AUTOSAR XML (schema 00049)
package /MICROSAR/StbM_swc/DataTypes
  21 x impl type:
    StbM_SynchronizedTimeBaseType: range raw 0..65535, implementation-data-type=uint16
    StbM_TimeBaseStatusType:
      compu {mask 1: 0=FALSE (TIMEOUT__FALSE), mask 1: 1=TRUE (TIMEOUT), mask 4: 0=FALSE (SYNC_TO_GATEWAY__FALSE), mask 4: 4=TRUE (SYNC_TO_GATEWAY), mask 8: 0=FALSE (GLOBAL_TIME_BASE__FALSE), mask 8: 8=TRUE (GLOBAL_TIME_BASE), mask 16: 0=FALSE (TIMELEAP_FUTURE__FALSE), mask 16: 16=TRUE (TIMELEAP_FUTURE), mask 32: 0=FALSE (TIMELEAP_PAST__FALSE), mask 32: 32=TRUE (TIMELEAP_PAST)}
      range raw 0..63
      implementation-data-type=uint8
    StbM_CloneConfigType: compu {mask 1: 0=FALSE (DEFERRED_COPY__FALSE), mask 1: 1=TRUE (DEFERRED_COPY), mask 2: 0=FALSE (IMMEDIATE_TX__FALSE), mask 2: 2=TRUE (IMMEDIATE_TX), mask 4: 0=FALSE (APPLY_RATE__FALSE), mask 4: 4=TRUE (APPLY_RATE)}, range raw 0..7, implementation-data-type=uint8
    StbM_TimeStampType: category=STRUCTURE
      4 x element, all with category=TYPE_REFERENCE:
        timeBaseStatus: implementation-data-type=StbM_TimeBaseStatusType
        nanoseconds: implementation-data-type=uint32
        seconds: implementation-data-type=uint32
        secondsHi: implementation-data-type=uint16
    StbM_UserDataType: category=STRUCTURE
      4 x element, all with category=TYPE_REFERENCE, implementation-data-type=uint8:
        userDataLength
        userByte{0..2}
    StbM_RateDeviationType: implementation-data-type=sint16
    StbM_SyncRecordTableHeadType: category=STRUCTURE
      element SynchronizedTimeDomain: implementation-data-type=uint8
      element HWfrequency: implementation-data-type=uint32
      element HWprescaler: implementation-data-type=uint32
    StbM_SyncRecordTableBlockType: category=STRUCTURE
      8 x element, all with category=TYPE_REFERENCE:
        GlbSeconds: implementation-data-type=uint32
        GlbNanoSeconds: implementation-data-type=uint32
        TimeBaseStatus: implementation-data-type=StbM_TimeBaseStatusType
        VirtualLocalTimeLow: implementation-data-type=uint32
        RateDeviation: implementation-data-type=sint16
        LocSeconds: implementation-data-type=uint32
        LocNanoSeconds: implementation-data-type=uint32
        PathDelay: implementation-data-type=uint32
    StbM_OffsetRecordTableHeadType: category=STRUCTURE
      element OffsetTimeDomain: implementation-data-type=uint8
    StbM_OffsetRecordTableBlockType: category=STRUCTURE
      element GlbSeconds: implementation-data-type=uint32
      element GlbNanoSeconds: implementation-data-type=uint32
      element TimeBaseStatus: implementation-data-type=StbM_TimeBaseStatusType
    StbM_PortIdType: category=STRUCTURE
      element clockIdentity: implementation-data-type=uint64
      element portNumber: implementation-data-type=uint16
    StbM_TimeStampShortType: category=STRUCTURE
      element nanoseconds: implementation-data-type=uint32
      element seconds: implementation-data-type=uint32
    StbM_VirtualLocalTimeType: category=STRUCTURE
      element nanosecondsLo: implementation-data-type=uint32
      element nanosecondsHi: implementation-data-type=uint32
    StbM_EthTimeMasterMeasurementType: category=STRUCTURE
      5 x element, all with category=TYPE_REFERENCE:
        sequenceId: implementation-data-type=uint16
        sourcePortId: implementation-data-type=StbM_PortIdType
        syncEgressTimestamp: implementation-data-type=StbM_VirtualLocalTimeType
        preciseOriginTimestamp: implementation-data-type=StbM_TimeStampShortType
        correctionField: implementation-data-type=sint64
    StbM_EthTimeSlaveMeasurementType: category=STRUCTURE
      8 x element, all with category=TYPE_REFERENCE:
        sequenceId: implementation-data-type=uint16
        sourcePortId: implementation-data-type=StbM_PortIdType
        syncIngressTimestamp: implementation-data-type=StbM_VirtualLocalTimeType
        preciseOriginTimestamp: implementation-data-type=StbM_TimeStampShortType
        correctionField: implementation-data-type=sint64
        pDelay: implementation-data-type=uint32
        referenceLocalTimestamp: implementation-data-type=StbM_VirtualLocalTimeType
        referenceGlobalTimestamp: implementation-data-type=StbM_TimeStampShortType
    StbM_PdelayInitiatorMeasurementType: category=STRUCTURE
      10 x element, all with category=TYPE_REFERENCE:
        sequenceId: implementation-data-type=uint16
        requestPortId: implementation-data-type=StbM_PortIdType
        responsePortId: implementation-data-type=StbM_PortIdType
        requestOriginTimestamp: implementation-data-type=StbM_VirtualLocalTimeType
        responseReceiptTimestamp: implementation-data-type=StbM_VirtualLocalTimeType
        requestReceiptTimestamp: implementation-data-type=StbM_TimeStampShortType
        responseOriginTimestamp: implementation-data-type=StbM_TimeStampShortType
        referenceLocalTimestamp: implementation-data-type=StbM_VirtualLocalTimeType
        referenceGlobalTimestamp: implementation-data-type=StbM_TimeStampShortType
        pdelay: implementation-data-type=uint32
    StbM_PdelayResponderMeasurementType: category=STRUCTURE
      7 x element, all with category=TYPE_REFERENCE:
        sequenceId: implementation-data-type=uint16
        requestPortId: implementation-data-type=StbM_PortIdType
        responsePortId: implementation-data-type=StbM_PortIdType
        requestReceiptTimestamp: implementation-data-type=StbM_VirtualLocalTimeType
        responseOriginTimestamp: implementation-data-type=StbM_VirtualLocalTimeType
        referenceLocalTimestamp: implementation-data-type=StbM_VirtualLocalTimeType
        referenceGlobalTimestamp: implementation-data-type=StbM_TimeStampShortType
    StbM_TimeDiffType: range raw -2147483648..2147483647, implementation-data-type=sint32
    StbM_TimeBaseNotificationType:
      compu {mask 1: 0=FALSE (EV_GLOBAL_TIME__FALSE), mask 1: 1=TRUE (EV_GLOBAL_TIME), mask 2: 0=FALSE (EV_TIMEOUT_OCCURRED__FALSE), mask 2: 2=TRUE (EV_TIMEOUT_OCCURRED), mask 4: 0=FALSE (EV_TIMEOUT_REMOVED__FALSE), mask 4: 4=TRUE (EV_TIMEOUT_REMOVED), mask 8: 0=FALSE (EV_TIMELEAP_FUTURE__FALSE), mask 8: 8=TRUE (EV_TIMELEAP_FUTURE), mask 16: 0=FALSE (EV_TIMELEAP_FUTURE_REMOVED__FALSE), mask 16: 16=TRUE (EV_TIMELEAP_FUTURE_REMOVED), mask 32: 0=FALSE (EV_TIMELEAP_PAST__FALSE), mask 32: 32=TRUE (EV_TIMELEAP_PAST), mask 64: 0=FALSE (EV_TIMELEAP_PAST_REMOVED__FALSE), mask 64: 64=TRUE (EV_TIMELEAP_PAST_REMOVED), mask 128: 0=FALSE (EV_SYNC_TO_SUBDOMAIN__FALSE), mask 128: 128=TRUE (EV_SYNC_TO_SUBDOMAIN), mask 256: 0=FALSE (EV_SYNC_TO_GLOBAL_MASTER__FALSE), mask 256: 256=TRUE (EV_SYNC_TO_GLOBAL_MASTER), mask 512: 0=FALSE (EV_RESYNC__FALSE), mask 512: 512=TRUE (EV_RESYNC), mask 1024: 0=FALSE (EV_RATECORRECTION__FALSE), mask 1024: 1024=TRUE (EV_RATECORRECTION)}
      range raw 0..4294967295
      implementation-data-type=uint32
    StbM_CustomerIdType: range raw 0..65535, implementation-data-type=uint16
    StbM_MasterConfigType: compu {0=STBM_SYSTEM_WIDE_MASTER_DISABLED, 1=STBM_SYSTEM_WIDE_MASTER_ENABLED}, range raw 0..255, implementation-data-type=uint8  # The value of this type is STBM_SYSTEM_WIDE_MASTER_ENABLED if and only if an ECU is configured as system wide master for a given timebase and STBM_SYSTEM_WIDE_MASTER_DISABLED otherwise.
package /MICROSAR/StbM_swc/Interfaces
  sender receiver interface StatusNotification: is-service=true, service-kind=SYNC-BASE-TIME-MANAGER
    data eventNotification: type=StbM_TimeBaseNotificationType
  4 x client server interface, all with is-service=true, service-kind=SYNC-BASE-TIME-MANAGER:
    GlobalTime_Slave_StbMSynchronizedTimeBase
      5 x operation, all with possible-error=[GlobalTime_Slave_StbMSynchronizedTimeBase/E_OK, GlobalTime_Slave_StbMSynchronizedTimeBase/E_NOT_OK]:
        GetCurrentTime
          arg timeStampPtr: type=StbM_TimeStampType, direction=OUT
          arg userDataPtr: type=StbM_UserDataType, direction=OUT
        GetRateDeviation
          arg rateDeviation: type=StbM_RateDeviationType, direction=OUT
        GetTimeLeap
          arg timeJump: type=StbM_TimeDiffType, direction=OUT
        GetTimeBaseStatus
          arg syncTimeBaseStatus: type=StbM_TimeBaseStatusType, direction=OUT
          arg offsetTimeBaseStatus: type=StbM_TimeBaseStatusType, direction=OUT
        GetSyncTimeRecordHead
          arg syncRecordTableHead: type=StbM_SyncRecordTableHeadType, direction=OUT
      error E_OK: error-code=0
      error E_NOT_OK: error-code=1
    StbM_MeasurementNotification_StbMSynchronizedTimeBase
      operation TimeRecordBlock_Callback: possible-error=[StbM_MeasurementNotification_StbMSynchronizedTimeBase/E_OK, StbM_MeasurementNotification_StbMSynchronizedTimeBase/E_NOT_OK]
        arg syncRecordTableBlock: type=StbM_SyncRecordTableBlockType, direction=IN
      error E_OK: error-code=0
      error E_NOT_OK: error-code=1
    GlobalTime_Slave_StbMSynchronizedTimeBase_CanTsync
      5 x operation, all with possible-error=[GlobalTime_Slave_StbMSynchronizedTimeBase_CanTsync/E_OK, GlobalTime_Slave_StbMSynchronizedTimeBase_CanTsync/E_NOT_OK]:
        GetCurrentTime
          arg timeStampPtr: type=StbM_TimeStampType, direction=OUT
          arg userDataPtr: type=StbM_UserDataType, direction=OUT
        GetRateDeviation
          arg rateDeviation: type=StbM_RateDeviationType, direction=OUT
        GetTimeLeap
          arg timeJump: type=StbM_TimeDiffType, direction=OUT
        GetTimeBaseStatus
          arg syncTimeBaseStatus: type=StbM_TimeBaseStatusType, direction=OUT
          arg offsetTimeBaseStatus: type=StbM_TimeBaseStatusType, direction=OUT
        GetSyncTimeRecordHead
          arg syncRecordTableHead: type=StbM_SyncRecordTableHeadType, direction=OUT
      error E_OK: error-code=0
      error E_NOT_OK: error-code=1
    StbM_MeasurementNotification_StbMSynchronizedTimeBase_CanTsync
      operation TimeRecordTsync_Callback: possible-error=[StbM_MeasurementNotification_StbMSynchronizedTimeBase_CanTsync/E_OK, StbM_MeasurementNotification_StbMSynchronizedTimeBase_CanTsync/E_NOT_OK]
        arg syncRecordTableBlock: type=StbM_SyncRecordTableBlockType, direction=IN
      error E_OK: error-code=0
      error E_NOT_OK: error-code=1
package /MICROSAR/StbM_swc/ComponentTypes
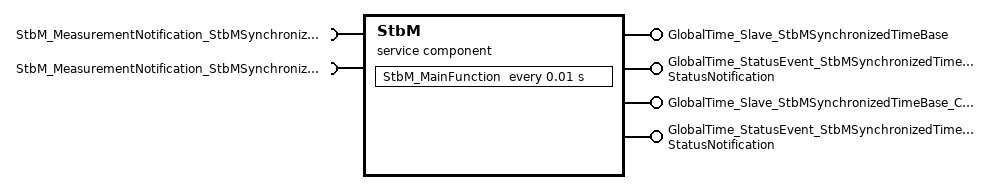
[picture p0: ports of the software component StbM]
  service sw component type StbM: category=SERVICE_COMPONENT
    provide port GlobalTime_Slave_StbMSynchronizedTimeBase: provided-interface=GlobalTime_Slave_StbMSynchronizedTimeBase
    provide port GlobalTime_StatusEvent_StbMSynchronizedTimeBase: nonqueued-sender-com-spec{data-element=eventNotification, init-value=0}, provided-interface=StatusNotification
    require port StbM_MeasurementNotification_StbMSynchronizedTimeBase: required-interface=StbM_MeasurementNotification_StbMSynchronizedTimeBase
    provide port GlobalTime_Slave_StbMSynchronizedTimeBase_CanTsync: provided-interface=GlobalTime_Slave_StbMSynchronizedTimeBase_CanTsync
    require port StbM_MeasurementNotification_StbMSynchronizedTimeBase_CanTsync: required-interface=StbM_MeasurementNotification_StbMSynchronizedTimeBase_CanTsync
    provide port GlobalTime_StatusEvent_StbMSynchronizedTimeBase_CanTsync: nonqueued-sender-com-spec{data-element=eventNotification, init-value=0}, provided-interface=StatusNotification
    behavior StbMInternalBehavior: handle-termination-and-restart=NO-SUPPORT, included-data-type-set=data-type=[StbM_SynchronizedTimeBaseType, StbM_TimeBaseStatusType, StbM_CloneConfigType, StbM_TimeStampType, StbM_UserDataType, StbM_RateDeviationType, StbM_SyncRecordTableHeadType, StbM_SyncRecordTableBlockType, StbM_OffsetRecordTableHeadType, StbM_OffsetRecordTableBlockType, StbM_PortIdType, StbM_TimeStampShortType, StbM_VirtualLocalTimeType, StbM_EthTimeMasterMeasurementType, StbM_EthTimeSlaveMeasurementType, StbM_PdelayInitiatorMeasurementType, StbM_PdelayResponderMeasurementType, StbM_TimeDiffType, StbM_TimeBaseNotificationType, StbM_CustomerIdType, StbM_MasterConfigType]
      timing event Timer_StbM_MainFunction: start-on-event=StbM_MainFunction, period=0.01
      10 x operation invoked event:
        OpEventGetCurrentTime_GetCurrentTime_GlobalTime_Slave_StbMSynchronizedTimeBase: start-on-event=GetCurrentTime, operation=GlobalTime_Slave_StbMSynchronizedTimeBase.GetCurrentTime
        OpEventGetRateDeviation_GetRateDeviation_GlobalTime_Slave_StbMSynchronizedTimeBase: start-on-event=GetRateDeviation, operation=GlobalTime_Slave_StbMSynchronizedTimeBase.GetRateDeviation
        OpEventGetTimeLeap_GetTimeLeap_GlobalTime_Slave_StbMSynchronizedTimeBase: start-on-event=GetTimeLeap, operation=GlobalTime_Slave_StbMSynchronizedTimeBase.GetTimeLeap
        OpEventGetTimeBaseStatus_GetTimeBaseStatus_GlobalTime_Slave_StbMSynchronizedTimeBase: start-on-event=GetTimeBaseStatus, operation=GlobalTime_Slave_StbMSynchronizedTimeBase.GetTimeBaseStatus
        OpEventGetSyncTimeRecordHead_GetSyncTimeRecordHead_GlobalTime_Slave_StbMSynchronizedTimeBase: start-on-event=GetSyncTimeRecordHead, operation=GlobalTime_Slave_StbMSynchronizedTimeBase.GetSyncTimeRecordHead
        OpEventGetCurrentTime_GetCurrentTime_GlobalTime_Slave_StbMSynchronizedTimeBase_CanTsync: start-on-event=GetCurrentTime, operation=GlobalTime_Slave_StbMSynchronizedTimeBase_CanTsync.GetCurrentTime
        OpEventGetRateDeviation_GetRateDeviation_GlobalTime_Slave_StbMSynchronizedTimeBase_CanTsync: start-on-event=GetRateDeviation, operation=GlobalTime_Slave_StbMSynchronizedTimeBase_CanTsync.GetRateDeviation
        OpEventGetTimeLeap_GetTimeLeap_GlobalTime_Slave_StbMSynchronizedTimeBase_CanTsync: start-on-event=GetTimeLeap, operation=GlobalTime_Slave_StbMSynchronizedTimeBase_CanTsync.GetTimeLeap
        OpEventGetTimeBaseStatus_GetTimeBaseStatus_GlobalTime_Slave_StbMSynchronizedTimeBase_CanTsync: start-on-event=GetTimeBaseStatus, operation=GlobalTime_Slave_StbMSynchronizedTimeBase_CanTsync.GetTimeBaseStatus
        OpEventGetSyncTimeRecordHead_GetSyncTimeRecordHead_GlobalTime_Slave_StbMSynchronizedTimeBase_CanTsync: start-on-event=GetSyncTimeRecordHead, operation=GlobalTime_Slave_StbMSynchronizedTimeBase_CanTsync.GetSyncTimeRecordHead
      port-api-options:
        {enable-take-address=true, indirect-api=false, port-defined-argument-value{value=0, value-type=StbM_SynchronizedTimeBaseType}, port=GlobalTime_Slave_StbMSynchronizedTimeBase}
        enable-take-address=true, indirect-api=false, port=GlobalTime_StatusEvent_StbMSynchronizedTimeBase
        enable-take-address=true, indirect-api=false, port=StbM_MeasurementNotification_StbMSynchronizedTimeBase
        {enable-take-address=true, indirect-api=false, port-defined-argument-value{value=1, value-type=StbM_SynchronizedTimeBaseType}, port=GlobalTime_Slave_StbMSynchronizedTimeBase_CanTsync}
        enable-take-address=true, indirect-api=false, port=StbM_MeasurementNotification_StbMSynchronizedTimeBase_CanTsync
        enable-take-address=true, indirect-api=false, port=GlobalTime_StatusEvent_StbMSynchronizedTimeBase_CanTsync
      6 x runnable:
        StbM_MainFunction
          data-send-points:
            access DataSendPointStbM_MainFunction_GlobalTime_StatusEvent_StbMSynchronizedTimeBase_eventNotification: accessed-variable=GlobalTime_StatusEvent_StbMSynchronizedTimeBase.eventNotification
            access DataSendPointStbM_MainFunction_GlobalTime_StatusEvent_StbMSynchronizedTimeBase_CanTsync_eventNotification: accessed-variable=GlobalTime_StatusEvent_StbMSynchronizedTimeBase_CanTsync.eventNotification
          sync call OpServerCallStbM_MainFunction_TimeRecordBlock_Callback_StbM_MeasurementNotification_StbMSynchronizedTimeBase: operation=StbM_MeasurementNotification_StbMSynchronizedTimeBase.TimeRecordBlock_Callback, timeout=0
          sync call OpServerCallStbM_MainFunction_TimeRecordTsync_Callback_StbM_MeasurementNotification_StbMSynchronizedTimeBase_CanTsync: operation=StbM_MeasurementNotification_StbMSynchronizedTimeBase_CanTsync.TimeRecordTsync_Callback, timeout=0
        GetCurrentTime: can-be-invoked-concurrently=true, symbol=StbM_GetCurrentTime
        GetRateDeviation: can-be-invoked-concurrently=true, symbol=StbM_GetRateDeviation
        GetTimeLeap: can-be-invoked-concurrently=true, symbol=StbM_GetTimeLeap
        GetTimeBaseStatus: can-be-invoked-concurrently=true, symbol=StbM_GetTimeBaseStatus
        GetSyncTimeRecordHead: can-be-invoked-concurrently=true, symbol=StbM_GetSyncTimeRecordHead
  swc implementation StbMImplementation: programming-language=C, behavior=StbMInternalBehavior
    resource consumption StbMResourceConsumption
      5 x memory section:
        StbM_CODE: sw-addrmethod=CODE, symbol=CODE
        StbM_CONST_UNSPECIFIED: alignment=UNSPECIFIED, sw-addrmethod=CONST, symbol=CONST_UNSPECIFIED
        StbM_VAR_NOINIT_UNSPECIFIED: alignment=UNSPECIFIED, sw-addrmethod=VAR_NO_INIT, symbol=VAR_NOINIT_UNSPECIFIED
        StbM_VAR_INIT_UNSPECIFIED: alignment=UNSPECIFIED, sw-addrmethod=VAR_INIT, symbol=VAR_INIT_UNSPECIFIED
        StbM_VAR_ZERO_INIT_UNSPECIFIED: alignment=UNSPECIFIED, sw-addrmethod=VAR_CLEARED, symbol=VAR_ZERO_INIT_UNSPECIFIED
